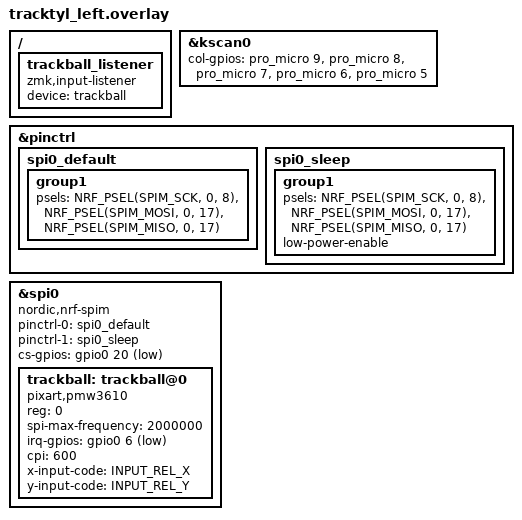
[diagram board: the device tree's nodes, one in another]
// tracktyl_left.overlay

#include "tracktyl.dtsi" // Notice that the main dtsi files are included in the overlay.

&kscan0 {
    col-gpios
        = <&pro_micro 9 GPIO_ACTIVE_HIGH> // col1 in the schematic
        , <&pro_micro 8 GPIO_ACTIVE_HIGH> // col2 in the schematic
        , <&pro_micro 7 GPIO_ACTIVE_HIGH> // col3 in the schematic
        , <&pro_micro 6 GPIO_ACTIVE_HIGH> // col4 in the schematic
        , <&pro_micro 5 GPIO_ACTIVE_HIGH> // col5 in the schematic
        ;
};

&pinctrl {
    spi0_default: spi0_default {
        group1 {
            psels = <NRF_PSEL(SPIM_SCK, 0, 8)>,
                <NRF_PSEL(SPIM_MOSI, 0, 17)>,
                <NRF_PSEL(SPIM_MISO, 0, 17)>;
        };
    };

    spi0_sleep: spi0_sleep {
        group1 {
            psels = <NRF_PSEL(SPIM_SCK, 0, 8)>,
                <NRF_PSEL(SPIM_MOSI, 0, 17)>,
                <NRF_PSEL(SPIM_MISO, 0, 17)>;
            low-power-enable;
        };
    };
};

&spi0 {
    status = "okay";
    compatible = "nordic,nrf-spim";
    pinctrl-0 = <&spi0_default>;
    pinctrl-1 = <&spi0_sleep>;
    pinctrl-names = "default", "sleep";
    cs-gpios = <&gpio0 20 GPIO_ACTIVE_LOW>;

    trackball: trackball@0 {
        status = "okay";
        compatible = "pixart,pmw3610";
        reg = <0>;
        spi-max-frequency = <2000000>;
        irq-gpios = <&gpio0 6 (GPIO_ACTIVE_LOW | GPIO_PULL_UP)>;
        cpi = <600>;
        //evt-type = <INPUT_EV_REL>;
        x-input-code = <INPUT_REL_X>;
        y-input-code = <INPUT_REL_Y>;
    };
};

/ {
  trackball_listener {
    compatible = "zmk,input-listener";
    device = <&trackball>;
  };
};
